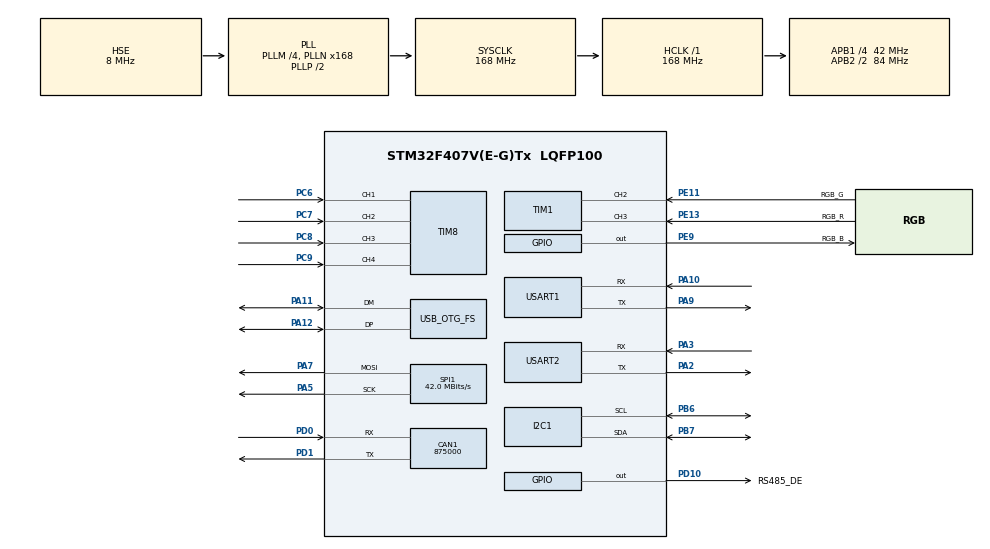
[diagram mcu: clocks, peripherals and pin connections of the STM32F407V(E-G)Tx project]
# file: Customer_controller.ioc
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CAN1.CalculateBaudRate=875000
CAN1.CalculateTimeBit=1142
CAN1.CalculateTimeQuantum=380.95238095238096
Mcu.Family=STM32F4
Mcu.Name=STM32F407V(E-G)Tx
Mcu.Package=LQFP100
NVIC.PriorityGroup=NVIC_PRIORITYGROUP_4
PA10.Mode=Asynchronous
PA10.Signal=USART1_RX
PA11.Mode=Host_Only
PA11.Signal=USB_OTG_FS_DM
PA12.Mode=Host_Only
PA12.Signal=USB_OTG_FS_DP
PA13.Mode=Serial_Wire
PA13.Signal=SYS_JTMS-SWDIO
PA14.Mode=Serial_Wire
PA14.Signal=SYS_JTCK-SWCLK
PA2.Mode=Asynchronous
PA2.Signal=USART2_TX
PA3.Mode=Asynchronous
PA3.Signal=USART2_RX
PA5.Mode=TX_Only_Simplex_Unidirect_Master
PA5.Signal=SPI1_SCK
PA7.Mode=TX_Only_Simplex_Unidirect_Master
PA7.Signal=SPI1_MOSI
PA9.Mode=Asynchronous
PA9.Signal=USART1_TX
PB3.Signal=SPI3_SCK
PB4.Signal=SPI3_MISO
PB5.Signal=SPI3_MOSI
PB6.Mode=I2C
PB6.Signal=I2C1_SCL
PB7.Mode=I2C
PB7.Signal=I2C1_SDA
PC6.Signal=S_TIM8_CH1
PC7.Signal=S_TIM8_CH2
PC8.Signal=S_TIM8_CH3
PC9.Signal=S_TIM8_CH4
PD0.Mode=CAN_Activate
PD0.Signal=CAN1_RX
PD1.Mode=CAN_Activate
PD1.Signal=CAN1_TX
PD10.GPIO_Label=RS485_DE
PD10.Signal=GPIO_Output
PD8.Signal=USART3_TX
PD9.Signal=USART3_RX
PE11.GPIO_Label=RGB_G
PE11.Signal=S_TIM1_CH2
PE13.GPIO_Label=RGB_R
PE13.Signal=S_TIM1_CH3
PE9.GPIO_Label=RGB_B
PE9.Signal=GPIO_Output
PH0-OSC_IN.Mode=HSE-External-Clock-Source
PH0-OSC_IN.Signal=RCC_OSC_IN
PH1-OSC_OUT.Mode=HSE-External-Clock-Source
PH1-OSC_OUT.Signal=RCC_OSC_OUT
ProjectManager.HeapSize=0x200
ProjectManager.StackSize=0x400
ProjectManager.TargetToolchain=MDK-ARM V5
RCC.48MHZClocksFreq_Value=48000000
RCC.AHBFreq_Value=168000000
RCC.APB1CLKDivider=RCC_HCLK_DIV4
RCC.APB1Freq_Value=42000000
RCC.APB1TimFreq_Value=84000000
RCC.APB2CLKDivider=RCC_HCLK_DIV2
RCC.APB2Freq_Value=84000000
RCC.APB2TimFreq_Value=168000000
RCC.CortexFreq_Value=168000000
RCC.HCLKFreq_Value=168000000
RCC.HSE_VALUE=8000000
RCC.HSI_VALUE=16000000
RCC.LSE_VALUE=32768
RCC.PLLM=4
RCC.PLLN=168
RCC.PLLQ=7
RCC.SYSCLKFreq_VALUE=168000000
RCC.SYSCLKSource=RCC_SYSCLKSOURCE_PLLCLK
RCC.VCOOutputFreq_Value=336000000
SH.S_TIM1_CH2.0=TIM1_CH2,Input_Capture2_from_TI2
SH.S_TIM1_CH3.0=TIM1_CH3,Input_Capture3_from_TI3
SH.S_TIM8_CH1.0=TIM8_CH1,Input_Capture1_from_TI1
SH.S_TIM8_CH2.0=TIM8_CH2,Input_Capture2_from_TI2
SH.S_TIM8_CH3.0=TIM8_CH3,Input_Capture3_from_TI3
SH.S_TIM8_CH4.0=TIM8_CH4,Input_Capture4_from_TI4
SPI1.CalculateBaudRate=42.0 MBits/s
SPI1.Direction=SPI_DIRECTION_2LINES
SPI1.Mode=SPI_MODE_MASTER
SPI1.VirtualType=VM_MASTER
TIM1.Channel-Input_Capture2_from_TI2=TIM_CHANNEL_2
TIM1.Channel-Input_Capture3_from_TI3=TIM_CHANNEL_3
TIM8.Channel-Input_Capture1_from_TI1=TIM_CHANNEL_1
TIM8.Channel-Input_Capture2_from_TI2=TIM_CHANNEL_2
TIM8.Channel-Input_Capture3_from_TI3=TIM_CHANNEL_3
TIM8.Channel-Input_Capture4_from_TI4=TIM_CHANNEL_4
USART1.VirtualMode=VM_ASYNC
USART2.VirtualMode=VM_ASYNC
USB_OTG_FS.VirtualMode=Host_Only
USB_OTG_FS.phy_itface=HCD_PHY_EMBEDDED
board=custom

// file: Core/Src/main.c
/* USER CODE BEGIN Header */
/**
  ******************************************************************************
  * @file           : main.c
  * @brief          : Main program body
  ******************************************************************************
  * @attention
  *
  * Copyright (c) 2024 STMicroelectronics.
  * All rights reserved.
  *
  * This software is licensed under terms that can be found in the LICENSE file
  * in the root directory of this software component.
  * If no LICENSE file comes with this software, it is provided AS-IS.
  *
  ******************************************************************************
  */
/* USER CODE END Header */
#include "main.h"
#include "can.h"
#include "i2c.h"
#include "spi.h"
#include "tim.h"
#include "usart.h"
#include "usb_otg.h"
#include "gpio.h"

void SystemClock_Config(void);

int main(void)
{

  /* MCU Configuration--------------------------------------------------------*/

  /* Reset of all peripherals, Initializes the Flash interface and the Systick. */
  HAL_Init();

  /* Configure the system clock */
  SystemClock_Config();

  /* Initialize all configured peripherals */
  MX_GPIO_Init();
  MX_CAN1_Init();
  MX_I2C1_Init();
  MX_USART1_UART_Init();
  MX_USB_OTG_FS_HCD_Init();
  MX_SPI1_Init();
  MX_TIM1_Init();
  MX_TIM8_Init();
  MX_USART2_UART_Init();

  /* Infinite loop */
  while (1)
  {

    /* USER CODE BEGIN 3 */
	  HAL_GPIO_WritePin (RGB_B_GPIO_Port ,RGB_B_Pin ,GPIO_PIN_SET );
	  HAL_Delay (500);
	  HAL_GPIO_WritePin (RGB_B_GPIO_Port ,RGB_B_Pin ,GPIO_PIN_RESET);
	  HAL_Delay (500);

  }
  /* USER CODE END 3 */
}

void SystemClock_Config(void)
{
  RCC_OscInitTypeDef RCC_OscInitStruct = {0};
  RCC_ClkInitTypeDef RCC_ClkInitStruct = {0};

  /** Configure the main internal regulator output voltage
  */
  __HAL_RCC_PWR_CLK_ENABLE();
  __HAL_PWR_VOLTAGESCALING_CONFIG(PWR_REGULATOR_VOLTAGE_SCALE1);

  /** Initializes the RCC Oscillators according to the specified parameters
  * in the RCC_OscInitTypeDef structure.
  */
  RCC_OscInitStruct.OscillatorType = RCC_OSCILLATORTYPE_HSE;
  RCC_OscInitStruct.HSEState = RCC_HSE_BYPASS;
  RCC_OscInitStruct.PLL.PLLState = RCC_PLL_ON;
  RCC_OscInitStruct.PLL.PLLSource = RCC_PLLSOURCE_HSE;
  RCC_OscInitStruct.PLL.PLLM = 4;
  RCC_OscInitStruct.PLL.PLLN = 168;
  RCC_OscInitStruct.PLL.PLLP = RCC_PLLP_DIV2;
  RCC_OscInitStruct.PLL.PLLQ = 7;
  if (HAL_RCC_OscConfig(&RCC_OscInitStruct) != HAL_OK)
  {
    Error_Handler();
  }

  /** Initializes the CPU, AHB and APB buses clocks
  */
  RCC_ClkInitStruct.ClockType = RCC_CLOCKTYPE_HCLK|RCC_CLOCKTYPE_SYSCLK
                              |RCC_CLOCKTYPE_PCLK1|RCC_CLOCKTYPE_PCLK2;
  RCC_ClkInitStruct.SYSCLKSource = RCC_SYSCLKSOURCE_PLLCLK;
  RCC_ClkInitStruct.AHBCLKDivider = RCC_SYSCLK_DIV1;
  RCC_ClkInitStruct.APB1CLKDivider = RCC_HCLK_DIV4;
  RCC_ClkInitStruct.APB2CLKDivider = RCC_HCLK_DIV2;

  if (HAL_RCC_ClockConfig(&RCC_ClkInitStruct, FLASH_LATENCY_5) != HAL_OK)
  {
    Error_Handler();
  }
}

void Error_Handler(void)
{
  __disable_irq();
  while (1)
  {
  }
}
